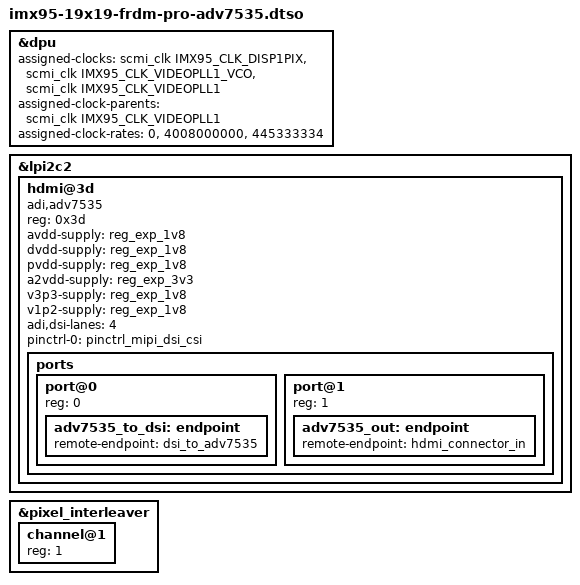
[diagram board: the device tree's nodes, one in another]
// SPDX-License-Identifier: (GPL-2.0+ OR MIT)
/*
 * Copyright 2026 NXP
 */

#include "imx95-clock.h"
#include "imx95-adv7535-common.dtsi"

&dpu {
	assigned-clocks = <&scmi_clk IMX95_CLK_DISP1PIX>,
			  <&scmi_clk IMX95_CLK_VIDEOPLL1_VCO>,
			  <&scmi_clk IMX95_CLK_VIDEOPLL1>;
	assigned-clock-parents = <&scmi_clk IMX95_CLK_VIDEOPLL1>;
	assigned-clock-rates = <0>, <4008000000>, <445333334>;
};

&lpi2c2 {
	#address-cells = <1>;
	#size-cells = <0>;

	hdmi@3d {
		compatible = "adi,adv7535";
		reg = <0x3d>;
		avdd-supply = <&reg_exp_1v8>;
		dvdd-supply = <&reg_exp_1v8>;
		pvdd-supply = <&reg_exp_1v8>;
		a2vdd-supply = <&reg_exp_3v3>;
		v3p3-supply = <&reg_exp_1v8>;
		v1p2-supply = <&reg_exp_1v8>;
		adi,dsi-lanes = <4>;
		pinctrl-names = "default";
		pinctrl-0 = <&pinctrl_mipi_dsi_csi>;

		ports {
			#address-cells = <1>;
			#size-cells = <0>;

			port@0 {
				reg = <0>;

				adv7535_to_dsi: endpoint {
					remote-endpoint = <&dsi_to_adv7535>;
				};
			};

			port@1 {
				reg = <1>;

				adv7535_out: endpoint {
					remote-endpoint = <&hdmi_connector_in>;
				};
			};
		};
	};
};

&pixel_interleaver {
	#address-cells = <1>;
	#size-cells = <0>;
	status = "okay";

	channel@1 {
		reg = <1>;
		status = "okay";
	};
};
